# psoc4100sp register map
Vendor: Cypress Semiconductor; Series: PSoC4100Sp; File version: 1.0
CPU: CM0PLUS r0p1, little endian, no MPU, no FPU, VTOR, 2 interrupt priority bits
Registers are 32-bit, read-write, reset 0x0 unless marked. A register's access mark holds for its fields unless they carry their own. Offsets are from the block's base; [hi:lo] are bit positions; <NAME> marks a mode.

## EXCO — ECO+PLL as SRSSLT clk_eco external source
Base 0x402F0000
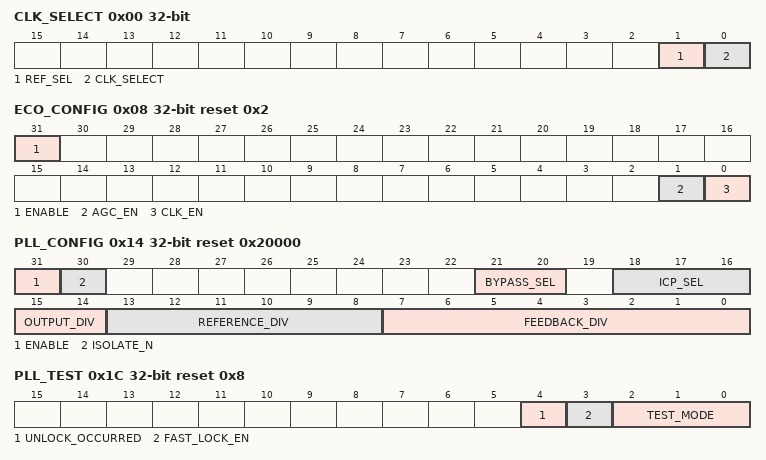
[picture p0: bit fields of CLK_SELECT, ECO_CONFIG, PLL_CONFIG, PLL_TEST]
0x00 CLK_SELECT — Clock Select Register
  [1] REF_SEL — Select source for PLL reference 0: from ECO 1: from external reference
  [0] CLK_SELECT — When PLL_CONFIG.ENABLE=0, then clk_eco=clk_osc. When PLL_CONFIG.ENABLE=1 then BYPASS_SEL and PLL_STATUS.LOCKED also affect this control point. CLK_SELECT: 0: PLL_CONFIG.BYPASS=0x, PLL_STATUS.LOCKED = 0: clk_eco=clk_osc PLL_CONFIG.BYPASS=0x, PLL_STATUS.LOCKED = 1: clk_eco=clk_pll PLL_CONFIG.BYPASS=10, PLL_STATUS.LOCKED = x: clk_eco=clk_osc PLL_CONFIG.BYPASS=11, PLL_STATUS.LOCKED = x: clk_eco=clk_pll 1: PLL_CONFIG.BYPASS=xx, PLL_STATUS.LOCKED = x: clk_eco=clk_pl
0x08 ECO_CONFIG reset 0x2 — ECO Configuration Register
  [31] ENABLE — Master enable for ECO oscillator. Refer to CLK_EN for sequencing.
  [1] AGC_EN — Automatic Gain Control (AGC) enable. When set, the oscillation amplitude is controlled to the level selected by ECO_TRIM0.ATRIM. When low, the amplitude is not explicitly controlled and will grow until it saturates to the supply rail (1.8V nom). WARNING: use care when disabling AGC because driving a crystal beyond its rated limit can permanently damage the crystal.
  [0] CLK_EN — Clock Enable. When enabling the clock, first write ENABLE=1, wait at least 10us, and then write CLK_EN=1. When disabling, clearing both CLK_EN=0 and ENABLE=0 can be done in the same AHB write
0x0C ECO_STATUS ro
  [0] WATCHDOG_ERROR — This bit is set to 1 if the oscillator is stuck. The ECO clock is gated off during a watchdog error condition. Due to internal synchonization, the clock is stopped two cycles after an error condition is observed and ungated two cycles after the error condition is resolved.
0x14 PLL_CONFIG reset 0x20000 — PLL Configuration Register
  [31] ENABLE — Master enable for PLL power gate. Refer to ISOLATE_N field for required sequencing. 0: Block is powered off, also forces clk_eco = clk_osc - See CLK_SELECT.CLK_SELECT description. 1: Block is powered on
  [30] ISOLATE_N — Isolation control of PLL outputs. This also internally resets the PLL. De-assert >= 5us after ENABLE=1. Assertion can happen in same write as ENABLE=0. Do not change while PLL output is selected. 0: Isolate outputs; Precharge PLL control voltage if PLL0_TEST.FAST_LOCK_EN is set to 1. 1: Do not isolate outputs
  [21:20] BYPASS_SEL — Selects the source of the system PLL0 clock. See also CLK_SELECT.CLK_SELECT for effect on clk_eco selection.
    0=AUTO (Automatic using lock indicator. When unlocked, automatically selects PLL reference input (bypass mode). When locked, automatically selects PLL output.); 1=AUTO1 (Same as AUTO); 2=PLL_REF (Select PLL reference input (bypass mode). Ignores lock indicator); 3=PLL_OUT (Select PLL output. Ignores lock indicator.)
  [18:16] ICP_SEL — Programmable charge pump current between 0uA and 7uA. Do not change while the PLL output is selected. For functional operation, the value must be set according to the PLL output frequency Fout (measured before the output divider): 0: 0uA (Hi-Z) Engineering use only 1: 1uA. Engineering use only 2: 2uA. Use when Fout <= 67MHz 3: 3uA. Use when Fout > 67MHz 4-7: 4uA-7uA. Engineering use only
  [15:14] OUTPUT_DIV — Control bits for Output divider. Do not change while PLL output is selected.
    0=PASS (Pass Through); 1=DIV2 (Divide by 2); 2=DIV4 (Divide by 4); 3=DIV8 (Divide by 8)
  [13:8] REFERENCE_DIV — Control bits for reference divider: Divide by 2=0001, ..., divide by 64=111111. Do not change while PLL output is selected.
  [7:0] FEEDBACK_DIV — Control bits for feedback divider: Valid divide is 8-255. Do not change while PLL output is selected.
0x18 PLL_STATUS ro
  [0] LOCKED — PLL Lock Indicator - See CLK_SELECT.CLK_SELECT description for interaction with clk_eco selection.
0x1C PLL_TEST reset 0x8
  [4] UNLOCK_OCCURRED — This bit sets whenever the PLL Lock bit goes low, and stays set until cleared by firmware. This is a diagnostic bit used for char and validation.
  [3] FAST_LOCK_EN — Fast Lock Enable - Speeds up the lock time when set to 1. When ISOLATE_N is high, the PLL control voltage will be precharged to reduce time spent acquiring frequency lock.
  [2:0] TEST_MODE
    0=NORMAL (Normal Operation); 1=TEST_VC_LKG (Vcontrol Leakage Test Mode Measure frequency drift over time to indirectly measure leakage on Vcontrol); 2=TEST_CP_DN (Charge Pump Down Current Test Mode With ICPSEL>0, directly measure charge pump up current on Vcontrol With ICPSEL=0, directly measure leakage on Vcontrol With ICPSEL=0, FAST_LOCK_EN=0 and ISOLATE_N=0, directly measure discharge current on Vcontrol With ICPSEL=0, FAST_LOCK_EN=1 and ISOLATE_N=0, directly measure precharge current on Vcontrol); 3=TEST_CP_UP (Charge Pump Up Current Test Mode With ICPSEL>0, directly measure charge pump up current on Vcontrol With ICPSEL=0, directly measure leakage on Vcontrol With ICPSEL=0, FAST_LOCK_EN=0 and ISOLATE_N=0, directly measure discharge current on Vcontrol With ICPSEL=0, FAST_LOCK_EN=1 and ISOLATE_N=0, directly measure precharge current on Vcontrol); 4=USER_EXT_FL (User Mode with Extended Fast Lock Precharge); 5=TEST_CTR_PQ (Reference and Feedback Counter Test Mode); 6=TEST_LD_DLY (Lock Detector Delay Line Test Mode); 7=TEST_CTR_ALT (Lock Detector Wait and Extended Fast Lock Counter Test Mode With ICPSEL=0 and Reference Clock stopped directly measure precharge current on Vcontrol With ICPSEL=0 and Reference Clock running directly measure leakage on Vcontrol)
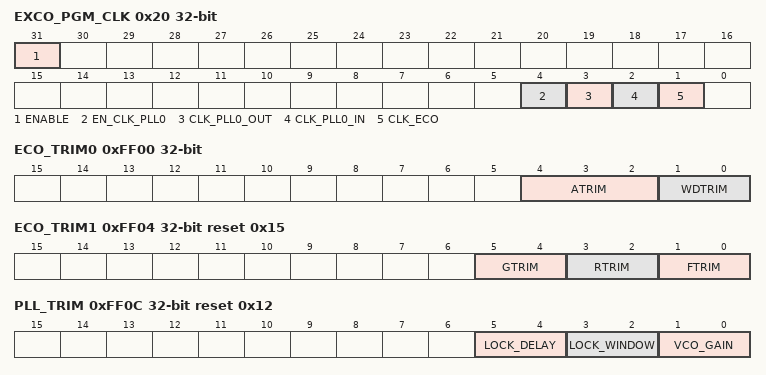
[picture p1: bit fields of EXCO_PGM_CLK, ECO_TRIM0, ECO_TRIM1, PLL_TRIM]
0x20 EXCO_PGM_CLK — EXCO Program Clock
  [31] ENABLE — Enable bit-banging test capability in this register.
  [4] EN_CLK_PLL0 — Bit bang en_clk_pll0
  [3] CLK_PLL0_OUT — Bit bang clk_pll0_out
  [2] CLK_PLL0_IN ro — Observation point for clk_pll0_in
  [1] CLK_ECO — Bit bang clk_eco
0xFF00 ECO_TRIM0
  [4:2] ATRIM — Amplitude trim to set the crystal drive level when ECO_CONFIG.AGC_EN=1. WARNING: use care when setting this field because driving a crystal beyond its rated limit can permanently damage the crystal. 0x0 - 0.3Vpp 0x1 - 0.4Vpp 0x2 - 0.5Vpp 0x3 - 0.6Vpp 0x4 - 0.7Vpp 0x5 - 0.8Vpp 0x6 - 0.9Vpp 0x7 - 1.0Vpp
  [1:0] WDTRIM — Watch Dog Trim - Delta voltage below stead state level 0x0 - 0.05V 0x1 - 0.1V 0x2 - 0.15V 0x3 - 0.2V
0xFF04 ECO_TRIM1 reset 0x15
  [5:4] GTRIM — Gain Trim - Startup time
  [3:2] RTRIM — Feedback resistor Trim
  [1:0] FTRIM — Filter Trim - 3rd harmonic oscillation
0xFF08 ECO_TRIM2 reset 0x20
  [5:0] ITRIM — Current Trim
0xFF0C PLL_TRIM reset 0x12
  [5:4] LOCK_DELAY — Selects the number of PLL phase frequency detector cycles that the phase error must be in range before declaring lock. (PFD clock cycle = Clock Reference Period/REFERENCE_DIV)
    0=PFD_CLK_16 (16 PFD clock cycles); 1=PFD_CLK_32 (32 PFD clock cycles); 2=PFD_CLK_48 (48 PFD clock cycles); 3=PFD_CLK_64 (64 PFD clock cycles)
  [3:2] LOCK_WINDOW — Selects the allowed phase error before declaring the PLL Unlocked
    0=DELAY_25NS; 1=DELAY_50NS; 2=DELAY_75NS; 3=DELAY_100NS
  [1:0] VCO_GAIN — Programmable VCO frequency characteristic at high freq - set to <10>
